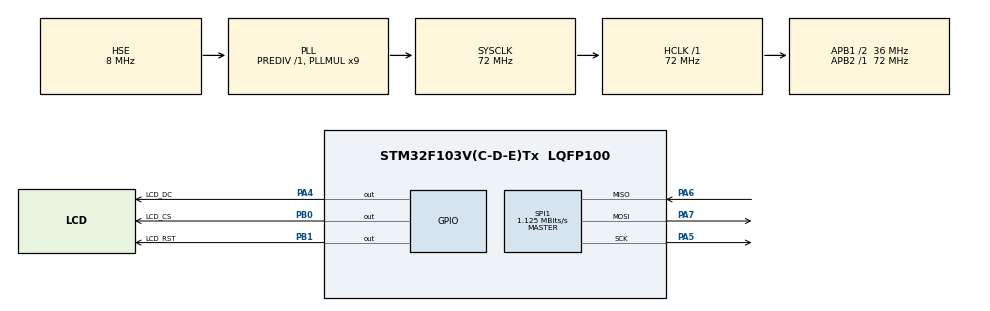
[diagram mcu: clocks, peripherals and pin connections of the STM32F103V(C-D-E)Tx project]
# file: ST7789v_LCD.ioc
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Mcu.Family=STM32F1
Mcu.Name=STM32F103V(C-D-E)Tx
Mcu.Package=LQFP100
NVIC.PriorityGroup=NVIC_PRIORITYGROUP_4
OSC_IN.Mode=HSE-External-Oscillator
OSC_IN.Signal=RCC_OSC_IN
OSC_OUT.Mode=HSE-External-Oscillator
OSC_OUT.Signal=RCC_OSC_OUT
PA13.Mode=Serial_Wire
PA13.Signal=SYS_JTMS-SWDIO
PA14.Mode=Serial_Wire
PA14.Signal=SYS_JTCK-SWCLK
PA4.GPIO_Label=LCD_DC
PA4.GPIO_PuPd=GPIO_PULLUP
PA4.GPIO_Speed=GPIO_SPEED_FREQ_HIGH
PA4.PinState=GPIO_PIN_SET
PA4.Signal=GPIO_Output
PA5.Mode=Full_Duplex_Master
PA5.Signal=SPI1_SCK
PA6.Mode=Full_Duplex_Master
PA6.Signal=SPI1_MISO
PA7.Mode=Full_Duplex_Master
PA7.Signal=SPI1_MOSI
PB0.GPIO_Label=LCD_CS
PB0.GPIO_PuPd=GPIO_PULLDOWN
PB0.GPIO_Speed=GPIO_SPEED_FREQ_HIGH
PB0.Signal=GPIO_Output
PB1.GPIO_Label=LCD_RST
PB1.GPIO_PuPd=GPIO_PULLUP
PB1.GPIO_Speed=GPIO_SPEED_FREQ_HIGH
PB1.PinState=GPIO_PIN_SET
PB1.Signal=GPIO_Output
PC14-OSC32_IN.Mode=LSE-External-Oscillator
PC14-OSC32_IN.Signal=RCC_OSC32_IN
PC15-OSC32_OUT.Mode=LSE-External-Oscillator
PC15-OSC32_OUT.Signal=RCC_OSC32_OUT
ProjectManager.HeapSize=0x200
ProjectManager.StackSize=0x400
ProjectManager.TargetToolchain=CMake
RCC.AHBFreq_Value=72000000
RCC.APB1CLKDivider=RCC_HCLK_DIV2
RCC.APB1Freq_Value=36000000
RCC.APB1TimFreq_Value=72000000
RCC.APB2Freq_Value=72000000
RCC.APB2TimFreq_Value=72000000
RCC.HCLKFreq_Value=72000000
RCC.PLLMUL=RCC_PLL_MUL9
RCC.PLLSourceVirtual=RCC_PLLSOURCE_HSE
RCC.SYSCLKFreq_VALUE=72000000
RCC.SYSCLKSource=RCC_SYSCLKSOURCE_PLLCLK
RCC.USBFreq_Value=72000000
SPI1.BaudRatePrescaler=SPI_BAUDRATEPRESCALER_64
SPI1.CLKPhase=SPI_PHASE_2EDGE
SPI1.CLKPolarity=SPI_POLARITY_HIGH
SPI1.CalculateBaudRate=1.125 MBits/s
SPI1.Direction=SPI_DIRECTION_2LINES
SPI1.Mode=SPI_MODE_MASTER
SPI1.VirtualType=VM_MASTER
board=custom

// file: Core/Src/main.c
/* USER CODE BEGIN Header */
/**
  ******************************************************************************
  * @file           : main.c
  * @brief          : Main program body
  ******************************************************************************
  * @attention
  *
  * Copyright (c) 2026 STMicroelectronics.
  * All rights reserved.
  *
  * This software is licensed under terms that can be found in the LICENSE file
  * in the root directory of this software component.
  * If no LICENSE file comes with this software, it is provided AS-IS.
  *
  ******************************************************************************
  */
/* USER CODE END Header */
#include "main.h"
#include "spi.h"
#include "gpio.h"

/* USER CODE BEGIN Includes */
#include "gui_guider.h"
#include "st7789v.h"
#include "lvgl.h"
#include "lv_port_disp.h"
/* USER CODE END Includes */

void SystemClock_Config(void);

int main(void)
{

  /* MCU Configuration--------------------------------------------------------*/

  /* Reset of all peripherals, Initializes the Flash interface and the Systick. */
  HAL_Init();

  /* Configure the system clock */
  SystemClock_Config();

  /* Initialize all configured peripherals */
  MX_GPIO_Init();
  MX_SPI1_Init();
  /* USER CODE BEGIN 2 */
  HAL_SPI_Transmit_DMA(&hspi1, NULL, 0);
  LCD_Init();

  lv_init();
  lv_port_disp_init();

  lv_ui guider_ui;
  setup_ui(&guider_ui);
  lv_label_set_text_fmt(guider_ui.screen_title_text,"\n在");
  HAL_Delay(100);
  lv_label_set_text_fmt(guider_ui.screen_title_text,"\n灯已打开");

  int i = 0;
  /* USER CODE END 2 */

  /* Infinite loop */
  while (1)
  {
    lv_task_handler(); // LVGL 任务
    HAL_Delay(5);

    lv_label_set_text_fmt(guider_ui.screen_humidity_label,"%d",i);
    i++;

    if (i == 100) {
      i = 0;
    }
  }
}

void SystemClock_Config(void)
{
  RCC_OscInitTypeDef RCC_OscInitStruct = {0};
  RCC_ClkInitTypeDef RCC_ClkInitStruct = {0};

  /** Initializes the RCC Oscillators according to the specified parameters
  * in the RCC_OscInitTypeDef structure.
  */
  RCC_OscInitStruct.OscillatorType = RCC_OSCILLATORTYPE_HSE;
  RCC_OscInitStruct.HSEState = RCC_HSE_ON;
  RCC_OscInitStruct.HSEPredivValue = RCC_HSE_PREDIV_DIV1;
  RCC_OscInitStruct.HSIState = RCC_HSI_ON;
  RCC_OscInitStruct.PLL.PLLState = RCC_PLL_ON;
  RCC_OscInitStruct.PLL.PLLSource = RCC_PLLSOURCE_HSE;
  RCC_OscInitStruct.PLL.PLLMUL = RCC_PLL_MUL9;
  if (HAL_RCC_OscConfig(&RCC_OscInitStruct) != HAL_OK)
  {
    Error_Handler();
  }

  /** Initializes the CPU, AHB and APB buses clocks
  */
  RCC_ClkInitStruct.ClockType = RCC_CLOCKTYPE_HCLK|RCC_CLOCKTYPE_SYSCLK
                              |RCC_CLOCKTYPE_PCLK1|RCC_CLOCKTYPE_PCLK2;
  RCC_ClkInitStruct.SYSCLKSource = RCC_SYSCLKSOURCE_PLLCLK;
  RCC_ClkInitStruct.AHBCLKDivider = RCC_SYSCLK_DIV1;
  RCC_ClkInitStruct.APB1CLKDivider = RCC_HCLK_DIV2;
  RCC_ClkInitStruct.APB2CLKDivider = RCC_HCLK_DIV1;

  if (HAL_RCC_ClockConfig(&RCC_ClkInitStruct, FLASH_LATENCY_2) != HAL_OK)
  {
    Error_Handler();
  }
}

void Error_Handler(void)
{
  __disable_irq();
  while (1)
  {
  }
}
